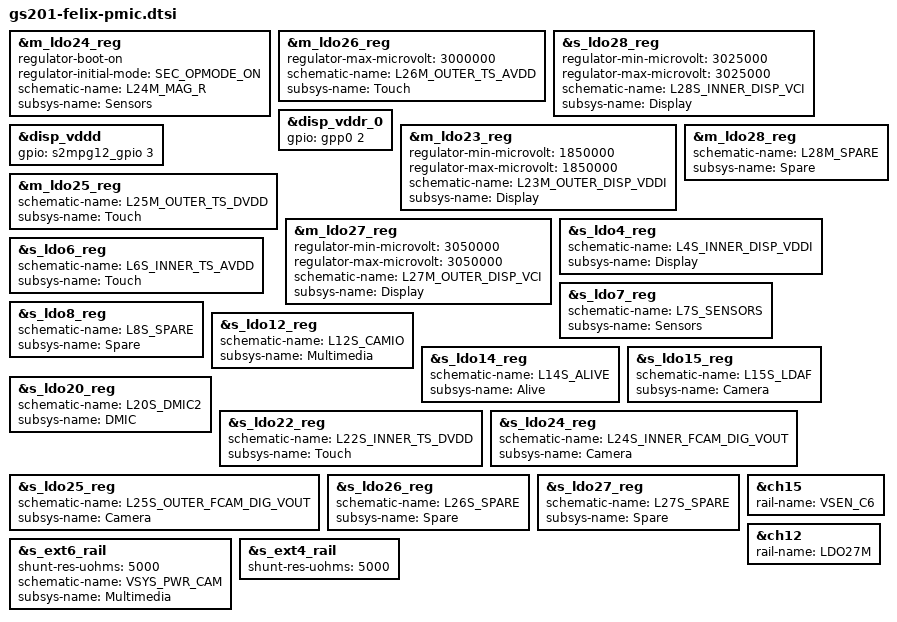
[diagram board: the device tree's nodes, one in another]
// SPDX-License-Identifier: GPL-2.0-only
/*
 * Felix-specific PMIC settings
 *
 * Copyright 2021 Google LLC.
 *
 */

/* Mag sensor: 1v8 power source. */
&m_ldo24_reg {
	regulator-boot-on;
	regulator-initial-mode = <SEC_OPMODE_ON>;
	schematic-name = "L24M_SENSORS";
	subsys-name = "Sensors";
};

/* Touch: touch controller requires 3.0v typ */
&m_ldo26_reg {
	regulator-max-microvolt = <3000000>;
	schematic-name = "L26M_OUTER_TS_AVDD";
	subsys-name = "Touch";
};

/* Display: inner vci-supply voltage */
&s_ldo28_reg {
	regulator-min-microvolt = <3025000>;
	regulator-max-microvolt = <3025000>;
	schematic-name = "L28M_SPARE";
	subsys-name = "Spare";
};

&disp_vddr_0 {
	status = "ok";
	gpio = <&gpp0 2 0>;
};

&disp_vddd {
    status = "ok";
    gpio = <&s2mpg12_gpio 3 GPIO_ACTIVE_HIGH>;
};

&m_ldo23_reg {
	regulator-min-microvolt = <1850000>;
	regulator-max-microvolt = <1850000>;
	schematic-name = "L23M_OUTER_DISP_VDDI";
	subsys-name = "Display";
};

&m_ldo24_reg {
	schematic-name = "L24M_MAG_R";
	subsys-name = "Sensors";
};

&m_ldo25_reg {
	schematic-name = "L25M_OUTER_TS_DVDD";
	subsys-name = "Touch";
};

&m_ldo27_reg {
	regulator-min-microvolt = <3050000>;
	regulator-max-microvolt = <3050000>;
	schematic-name = "L27M_OUTER_DISP_VCI";
	subsys-name = "Display";
};

&m_ldo28_reg {
	schematic-name = "L28M_SPARE";
	subsys-name = "Spare";
};

&s_ldo4_reg {
	schematic-name = "L4S_INNER_DISP_VDDI";
	subsys-name = "Display";
};

&s_ldo6_reg {
	schematic-name = "L6S_INNER_TS_AVDD";
	subsys-name = "Touch";
};

&s_ldo7_reg {
	schematic-name = "L7S_SENSORS";
	subsys-name = "Sensors";
};

&s_ldo8_reg {
	schematic-name = "L8S_SPARE";
	subsys-name = "Spare";
};

&s_ldo12_reg {
	schematic-name = "L12S_CAMIO";
	subsys-name = "Multimedia";
};

&s_ldo14_reg {
	schematic-name = "L14S_ALIVE";
	subsys-name = "Alive";
};

&s_ldo15_reg {
	schematic-name = "L15S_LDAF";
	subsys-name = "Camera";
};

&s_ldo20_reg {
	schematic-name = "L20S_DMIC2";
	subsys-name = "DMIC";
};

&s_ldo22_reg {
	schematic-name = "L22S_INNER_TS_DVDD";
	subsys-name = "Touch";
};

&s_ldo24_reg {
	schematic-name = "L24S_INNER_FCAM_DIG_VOUT";
	subsys-name = "Camera";
};

&s_ldo25_reg {
	schematic-name = "L25S_OUTER_FCAM_DIG_VOUT";
	subsys-name = "Camera";
};

&s_ldo26_reg {
	schematic-name = "L26S_SPARE";
	subsys-name = "Spare";
};

&s_ldo27_reg {
	schematic-name = "L27S_SPARE";
	subsys-name = "Spare";
};

&s_ldo28_reg {
	schematic-name = "L28S_INNER_DISP_VCI";
	subsys-name = "Display";
};

&s_ext6_rail {
	shunt-res-uohms = <5000>;
	schematic-name = "VSYS_PWR_CAM";
	subsys-name = "Multimedia";
};

/* replace L9S_GNSS_CORE to VSYS_PWR_CAM */
&ch15 {
	rail-name = "VSEN_C6";
};

/* L28M is spare on Felix */
&ch12 {
	rail-name = "LDO27M";
};

/* Dual display parallel sensing circuit */
&s_ext4_rail {
	shunt-res-uohms = <5000>;
};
